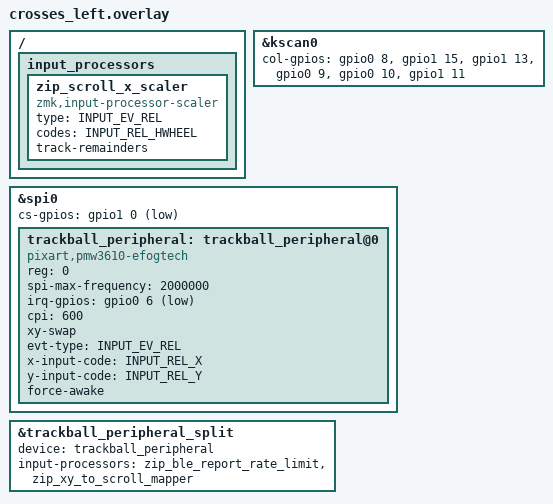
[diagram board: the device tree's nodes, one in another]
/*
 * Copyright (c) 2020 ZMK Contributors
 *
 * SPDX-License-Identifier: MIT
 */
 
#include "crosses.dtsi"
#include <zephyr/dt-bindings/input/input-event-codes.h>
#include <dt-bindings/zmk/input_transform.h>

&kscan0 {
	// 6 columns (official Crosses 54 left): outer col gpio0 8 added vs the 36 build
	col-gpios
		= <&gpio0 8 (GPIO_ACTIVE_HIGH | GPIO_PULL_DOWN)>
		, <&gpio1 15 (GPIO_ACTIVE_HIGH | GPIO_PULL_DOWN)>
		, <&gpio1 13 (GPIO_ACTIVE_HIGH | GPIO_PULL_DOWN)>
		, <&gpio0 9 (GPIO_ACTIVE_HIGH | GPIO_PULL_DOWN)>
		, <&gpio0 10 (GPIO_ACTIVE_HIGH | GPIO_PULL_DOWN)>
		, <&gpio1 11 (GPIO_ACTIVE_HIGH | GPIO_PULL_DOWN)>
		;
};


&spi0 {
    cs-gpios = <&gpio1 0 GPIO_ACTIVE_LOW>;

  trackball_peripheral: trackball_peripheral@0 {
        status = "okay";
    	compatible = "pixart,pmw3610-efogtech";
        reg = <0>;
        spi-max-frequency = <2000000>;
        irq-gpios = <&gpio0 6 (GPIO_ACTIVE_LOW | GPIO_PULL_UP)>;
        cpi = <600>;
		xy-swap;
    	evt-type = <INPUT_EV_REL>;
    	x-input-code = <INPUT_REL_X>;
    	y-input-code = <INPUT_REL_Y>;
    	force-awake;
    };
};

/ {
    input_processors {
        zip_scroll_x_scaler: zip_scroll_x_scaler {
            compatible = "zmk,input-processor-scaler";
            #input-processor-cells = <2>;
            type = <INPUT_EV_REL>;
            codes = <INPUT_REL_HWHEEL>;
            track-remainders;
        };
    };
};


// Overrides for the input-split child node
&trackball_peripheral_split {
	device = <&trackball_peripheral>;
	input-processors = <
		&zip_ble_report_rate_limit
        &zip_xy_to_scroll_mapper
        //&zip_scroll_x_scaler 0 1 //가로 스크롤 제한, 반응성 문제로 Central에서 처리로 변경
		//&zip_scroll_scaler 1 12 //스크롤 속도 조절, 반응성 문제로 Central에서 처리로 변경
    >;
};
